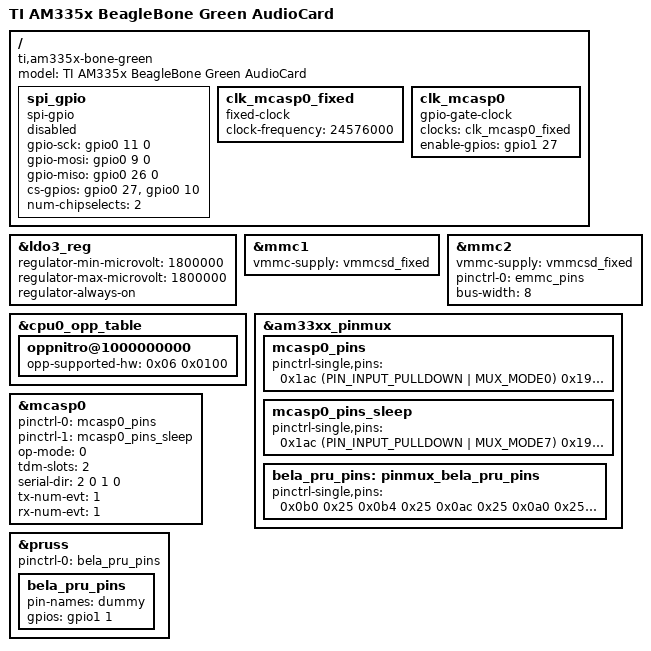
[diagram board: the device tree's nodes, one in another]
/*
 * Base device tree for BeagleBone Green with CTAG face2|4 Audio Card
 *
 * Author:  Henrik Langer <henni19790@googlemail.com>
 *			based on
				BeagleBone Black and BeagleBone Green device tree
 *
 * This program is free software; you can redistribute it and/or modify
 * it under the terms of the GNU General Public License version 2 as
 * published by the Free Software Foundation.
 */
/dts-v1/;

#include "am33xx.dtsi"
#include "am335x-bone-common.dtsi"
//#include "am33xx-overlay-edma-fix.dtsi" // leads to problems with SPI
#include "am33xx-pruss-uio.dtsi"
//#include "am33xx-pruss-rproc.dtsi"

/ {
	model = "TI AM335x BeagleBone Green AudioCard";
	compatible = "ti,am335x-bone-green", "ti,am335x-bone-black", "ti,am335x-bone", "ti,am33xx";

	/* 
		Optional SW SPI interface
		(see BB-CTAG-SW-8CH-00A0.dts for more details) 
	*/
	spi_gpio: spi_gpio {
		compatible = "spi-gpio";
		#address-cells = <1>;
		ranges;

		gpio-sck = <&gpio0 11 0>; 				//P8.32
		gpio-mosi = <&gpio0 9 0>;				//P8.33
		gpio-miso = <&gpio0 26 0>;				//P8.14
		cs-gpios = <&gpio0 27 0 &gpio0 10 0>; 	//P8.17 / P8.31
		num-chipselects = <2>;

		status = "disabled";
	};
};

&ldo3_reg {
	regulator-min-microvolt = <1800000>;
	regulator-max-microvolt = <1800000>;
	regulator-always-on;
};

&mmc1 {
	vmmc-supply = <&vmmcsd_fixed>;
};

&mmc2 {
	vmmc-supply = <&vmmcsd_fixed>;
	pinctrl-names = "default";
	pinctrl-0 = <&emmc_pins>;
	bus-width = <8>;
	status = "okay";
};

&cpu0_opp_table {
	/*
	 * All PG 2.0 silicon may not support 1GHz but some of the early
	 * BeagleBone Blacks have PG 2.0 silicon which is guaranteed
	 * to support 1GHz OPP so enable it for PG 2.0 on this board.
	 */
	oppnitro@1000000000 {
		opp-supported-hw = <0x06 0x0100>;
	};
};

&am33xx_pinmux {
	mcasp0_pins: mcasp0_pins {
		pinctrl-single,pins = <
			0x1ac (PIN_INPUT_PULLDOWN | MUX_MODE0)	/* mcasp0_ahclkx */
			0x19c (PIN_OUTPUT_PULLDOWN | MUX_MODE2) /* mcasp0_axr2 */
			0x194 (PIN_INPUT_PULLDOWN | MUX_MODE0)	/* mcasp0_fsx */
			0x190 (PIN_INPUT_PULLDOWN | MUX_MODE0)	/* mcasp0_aclkx */
			0x1a4 (PIN_INPUT_PULLDOWN | MUX_MODE0)	/* mcasp0_fsr */
			0x078 (PIN_INPUT_PULLDOWN | MUX_MODE6)	/* mcasp0_aclkr */
			0x198 (PIN_INPUT_PULLDOWN | MUX_MODE0)	/* mcasp0_axr0 */
			0x06c (PIN_OUTPUT_PULLDOWN | MUX_MODE7)	/* gpio1[27] (enable oscillator) */
		>;
	};

	mcasp0_pins_sleep: mcasp0_pins_sleep {
		pinctrl-single,pins = <
			0x1ac (PIN_INPUT_PULLDOWN | MUX_MODE7)	/* mcasp0_ahclkx */
			0x19c (PIN_INPUT_PULLDOWN | MUX_MODE7)	/* mcasp0_axr2 */
			0x194 (PIN_INPUT_PULLDOWN | MUX_MODE7)	/* mcasp0_fsx */
			0x190 (PIN_INPUT_PULLDOWN | MUX_MODE7)	/* mcasp0_aclkx */
			0x1a4 (PIN_INPUT_PULLDOWN | MUX_MODE0)	/* mcasp0_fsr */
			0x078 (PIN_INPUT_PULLDOWN | MUX_MODE6)	/* mcasp0_aclkr */
			0x198 (PIN_INPUT_PULLDOWN | MUX_MODE7)	/* mcasp0_axr0 */
			0x06c (PIN_INPUT_PULLDOWN | MUX_MODE7)	/* gpio1[27] */
		>;
	};

	/* Pinmux for PRU */
	bela_pru_pins: pinmux_bela_pru_pins {
		pinctrl-single,pins = <
			0x0b0 0x25 /* pr1_pru1_pru_r30_4, 	P8_41 | MODE5 | INPUT_PULLDOWN */
			0x0b4 0x25 /* pr1_pru1_pru_r30_5, 	P8_42 | MODE5 | INPUT_PULLDOWN */
			0x0ac 0x25 /* pr1_pru1_pru_r30_3, 	P8_44 | MODE5 | INPUT_PULLDOWN */
			0x0a0 0x25 /* pr1_pru1_pru_r30_0, 	P8_45 | MODE5 | INPUT_PULLDOWN */
			0x0a4 0x25 /* pr1_pru1_pru_r30_1, 	P8_46 | MODE5 | INPUT_PULLDOWN */
			0x0a8 0x25 /* pr1_pru1_pru_r30_2, 	P8_43 | MODE5 | INPUT_PULLDOWN */
			/* Is needed for pin multiplexing Bela button correctly */
			0x1a4 0x37 /* gpio3[19], 			P9_27 | MODE7 | INPUT_PULLUP */
		>;
	};
};

&mcasp0	{
	pinctrl-names = "default", "sleep";
	pinctrl-0 = <&mcasp0_pins>;
	pinctrl-1 = <&mcasp0_pins_sleep>;
	status = "okay";
	op-mode = <0>;	/* MCASP_IIS_MODE */
	tdm-slots = <2>;
	serial-dir = <	/* 0: INACTIVE, 1: TX, 2: RX */
			2 0 1 0
		>;
	tx-num-evt = <1>;
	rx-num-evt = <1>;
};

/ {
	clk_mcasp0_fixed: clk_mcasp0_fixed {
	      #clock-cells = <0>;
	      compatible = "fixed-clock";
	      clock-frequency = <24576000>;
	};

	clk_mcasp0: clk_mcasp0 {
	      #clock-cells = <0>;
	      compatible = "gpio-gate-clock";
	      clocks = <&clk_mcasp0_fixed>;
	      enable-gpios = <&gpio1 27 0>; /* BeagleBone Black Clk enable on GPIO1_27 */
	};
};

/* PRU config */
&pruss {
	pinctrl-names = "default";
	pinctrl-0 = <&bela_pru_pins>;
	
	status = "okay";

	/* Workaround for uio_pruss.c on 4.4.62 to prevent "No Children" error */
	bela_pru_pins {
		pin-names = "dummy";
		gpios = <&gpio1 1 2>;
		#gpio-cells = <2>;
	};
};
